# ESP32-C61 register map
Vendor: ESPRESSIF SYSTEMS (SHANGHAI) CO., LTD.; Series: ESP32 C-Series; File version: 1
CPU: RV32IMAC r0p0, little endian, no MPU, no FPU, 0 interrupt priority bits
Address unit: 32 bits
Registers are 32-bit, read-write, reset 0x0 unless marked. A register's access mark holds for its fields unless they carry their own. Offsets are from the block's base; [hi:lo] are bit positions; {n}, {i} and the like mark numbered series.

## CACHE (part 1 of 2) — CACHE Peripheral
Base 0x600C8000
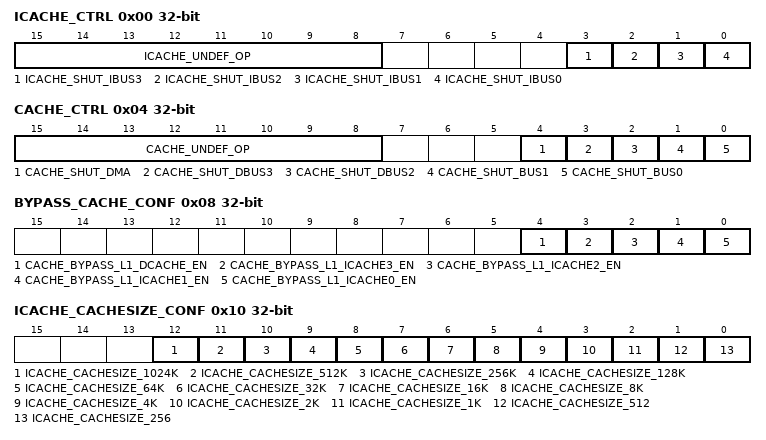
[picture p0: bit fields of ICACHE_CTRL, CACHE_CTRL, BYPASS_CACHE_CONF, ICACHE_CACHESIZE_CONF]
0x00 ICACHE_CTRL access per field — L1 instruction Cache(L1-ICache) control register
  [15:8] ICACHE_UNDEF_OP rw — Reserved
  [3] ICACHE_SHUT_IBUS3 ro — Reserved
  [2] ICACHE_SHUT_IBUS2 ro — Reserved
  [1] ICACHE_SHUT_IBUS1 rw — The bit is used to disable core1 ibus access L1-ICache, 0: enable, 1: disable
  [0] ICACHE_SHUT_IBUS0 rw — The bit is used to disable core0 ibus access L1-ICache, 0: enable, 1: disable
0x04 CACHE_CTRL access per field — L1 data Cache(L1-Cache) control register
  [15:8] CACHE_UNDEF_OP rw — Reserved
  [4] CACHE_SHUT_DMA ro — The bit is used to disable DMA access L1-Cache, 0: enable, 1: disable
  [3] CACHE_SHUT_DBUS3 ro — Reserved
  [2] CACHE_SHUT_DBUS2 ro — Reserved
  [1] CACHE_SHUT_BUS1 rw — The bit is used to disable core0 bus1 access L1-Cache, 0: enable, 1: disable
  [0] CACHE_SHUT_BUS0 rw — The bit is used to disable core0 bus0 access L1-Cache, 0: enable, 1: disable
0x08 BYPASS_CACHE_CONF ro — Bypass Cache configure register
  [4] CACHE_BYPASS_L1_DCACHE_EN — The bit is used to enable bypass L1-DCache. 0: disable bypass, 1: enable bypass.
  [3] CACHE_BYPASS_L1_ICACHE3_EN — Reserved
  [2] CACHE_BYPASS_L1_ICACHE2_EN — Reserved
  [1] CACHE_BYPASS_L1_ICACHE1_EN — The bit is used to enable bypass L1-ICache1. 0: disable bypass, 1: enable bypass.
  [0] CACHE_BYPASS_L1_ICACHE0_EN — The bit is used to enable bypass L1-ICache0. 0: disable bypass, 1: enable bypass.
0x0C CACHE_ATOMIC_CONF ro — L1 Cache atomic feature configure register
  [0] CACHE_ATOMIC_EN — The bit is used to enable atomic feature on L1-Cache when multiple cores access L1-Cache. 1: disable, 1: enable.
0x10 ICACHE_CACHESIZE_CONF ro — L1 instruction Cache CacheSize mode configure register
  [12] ICACHE_CACHESIZE_1024K — The field is used to configure cachesize of L1-ICache as 1024k bytes. This field and all other fields within this register is onehot.
  [11] ICACHE_CACHESIZE_512K — The field is used to configure cachesize of L1-ICache as 512k bytes. This field and all other fields within this register is onehot.
  [10] ICACHE_CACHESIZE_256K — The field is used to configure cachesize of L1-ICache as 256k bytes. This field and all other fields within this register is onehot.
  [9] ICACHE_CACHESIZE_128K — The field is used to configure cachesize of L1-ICache as 128k bytes. This field and all other fields within this register is onehot.
  [8] ICACHE_CACHESIZE_64K — The field is used to configure cachesize of L1-ICache as 64k bytes. This field and all other fields within this register is onehot.
  [7] ICACHE_CACHESIZE_32K — The field is used to configure cachesize of L1-ICache as 32k bytes. This field and all other fields within this register is onehot.
  [6] ICACHE_CACHESIZE_16K — The field is used to configure cachesize of L1-ICache as 16k bytes. This field and all other fields within this register is onehot.
  [5] ICACHE_CACHESIZE_8K — The field is used to configure cachesize of L1-ICache as 8k bytes. This field and all other fields within this register is onehot.
  [4] ICACHE_CACHESIZE_4K — The field is used to configure cachesize of L1-ICache as 4k bytes. This field and all other fields within this register is onehot.
  [3] ICACHE_CACHESIZE_2K — The field is used to configure cachesize of L1-ICache as 2k bytes. This field and all other fields within this register is onehot.
  [2] ICACHE_CACHESIZE_1K — The field is used to configure cachesize of L1-ICache as 1k bytes. This field and all other fields within this register is onehot.
  [1] ICACHE_CACHESIZE_512 — The field is used to configure cachesize of L1-ICache as 512 bytes. This field and all other fields within this register is onehot.
  [0] ICACHE_CACHESIZE_256 — The field is used to configure cachesize of L1-ICache as 256 bytes. This field and all other fields within this register is onehot.
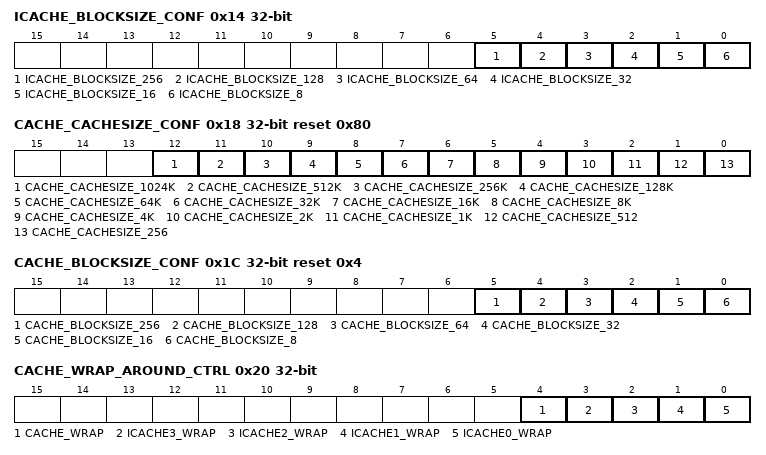
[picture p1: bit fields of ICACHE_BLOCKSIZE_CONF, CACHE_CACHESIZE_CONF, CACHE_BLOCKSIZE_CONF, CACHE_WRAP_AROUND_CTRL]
0x14 ICACHE_BLOCKSIZE_CONF ro — L1 instruction Cache BlockSize mode configure register
  [5] ICACHE_BLOCKSIZE_256 — The field is used to configureblocksize of L1-ICache as 256 bytes. This field and all other fields within this register is onehot.
  [4] ICACHE_BLOCKSIZE_128 — The field is used to configureblocksize of L1-ICache as 128 bytes. This field and all other fields within this register is onehot.
  [3] ICACHE_BLOCKSIZE_64 — The field is used to configureblocksize of L1-ICache as 64 bytes. This field and all other fields within this register is onehot.
  [2] ICACHE_BLOCKSIZE_32 — The field is used to configureblocksize of L1-ICache as 32 bytes. This field and all other fields within this register is onehot.
  [1] ICACHE_BLOCKSIZE_16 — The field is used to configureblocksize of L1-ICache as 16 bytes. This field and all other fields within this register is onehot.
  [0] ICACHE_BLOCKSIZE_8 — The field is used to configureblocksize of L1-ICache as 8 bytes. This field and all other fields within this register is onehot.
0x18 CACHE_CACHESIZE_CONF ro reset 0x80 — L1 data Cache CacheSize mode configure register
  [12] CACHE_CACHESIZE_1024K — The field is used to configure cachesize of L1-DCache as 1024k bytes. This field and all other fields within this register is onehot.
  [11] CACHE_CACHESIZE_512K — The field is used to configure cachesize of L1-DCache as 512k bytes. This field and all other fields within this register is onehot.
  [10] CACHE_CACHESIZE_256K — The field is used to configure cachesize of L1-DCache as 256k bytes. This field and all other fields within this register is onehot.
  [9] CACHE_CACHESIZE_128K — The field is used to configure cachesize of L1-DCache as 128k bytes. This field and all other fields within this register is onehot.
  [8] CACHE_CACHESIZE_64K — The field is used to configure cachesize of L1-DCache as 64k bytes. This field and all other fields within this register is onehot.
  [7] CACHE_CACHESIZE_32K — The field is used to configure cachesize of L1-DCache as 32k bytes. This field and all other fields within this register is onehot.
  [6] CACHE_CACHESIZE_16K — The field is used to configure cachesize of L1-DCache as 16k bytes. This field and all other fields within this register is onehot.
  [5] CACHE_CACHESIZE_8K — The field is used to configure cachesize of L1-DCache as 8k bytes. This field and all other fields within this register is onehot.
  [4] CACHE_CACHESIZE_4K — The field is used to configure cachesize of L1-DCache as 4k bytes. This field and all other fields within this register is onehot.
  [3] CACHE_CACHESIZE_2K — The field is used to configure cachesize of L1-DCache as 2k bytes. This field and all other fields within this register is onehot.
  [2] CACHE_CACHESIZE_1K — The field is used to configure cachesize of L1-DCache as 1k bytes. This field and all other fields within this register is onehot.
  [1] CACHE_CACHESIZE_512 — The field is used to configure cachesize of L1-DCache as 512 bytes. This field and all other fields within this register is onehot.
  [0] CACHE_CACHESIZE_256 — The field is used to configure cachesize of L1-DCache as 256 bytes. This field and all other fields within this register is onehot.
0x1C CACHE_BLOCKSIZE_CONF ro reset 0x4 — L1 data Cache BlockSize mode configure register
  [5] CACHE_BLOCKSIZE_256 — The field is used to configureblocksize of L1-DCache as 256 bytes. This field and all other fields within this register is onehot.
  [4] CACHE_BLOCKSIZE_128 — The field is used to configureblocksize of L1-DCache as 128 bytes. This field and all other fields within this register is onehot.
  [3] CACHE_BLOCKSIZE_64 — The field is used to configureblocksize of L1-DCache as 64 bytes. This field and all other fields within this register is onehot.
  [2] CACHE_BLOCKSIZE_32 — The field is used to configureblocksize of L1-DCache as 32 bytes. This field and all other fields within this register is onehot.
  [1] CACHE_BLOCKSIZE_16 — The field is used to configureblocksize of L1-DCache as 16 bytes. This field and all other fields within this register is onehot.
  [0] CACHE_BLOCKSIZE_8 — The field is used to configureblocksize of L1-DCache as 8 bytes. This field and all other fields within this register is onehot.
0x20 CACHE_WRAP_AROUND_CTRL access per field — Cache wrap around control register
  [4] CACHE_WRAP rw — Set this bit as 1 to enable L1-DCache wrap around mode.
  [3] ICACHE3_WRAP ro — Reserved
  [2] ICACHE2_WRAP ro — Reserved
  [1] ICACHE1_WRAP ro — Set this bit as 1 to enable L1-ICache1 wrap around mode.
  [0] ICACHE0_WRAP ro — Set this bit as 1 to enable L1-ICache0 wrap around mode.
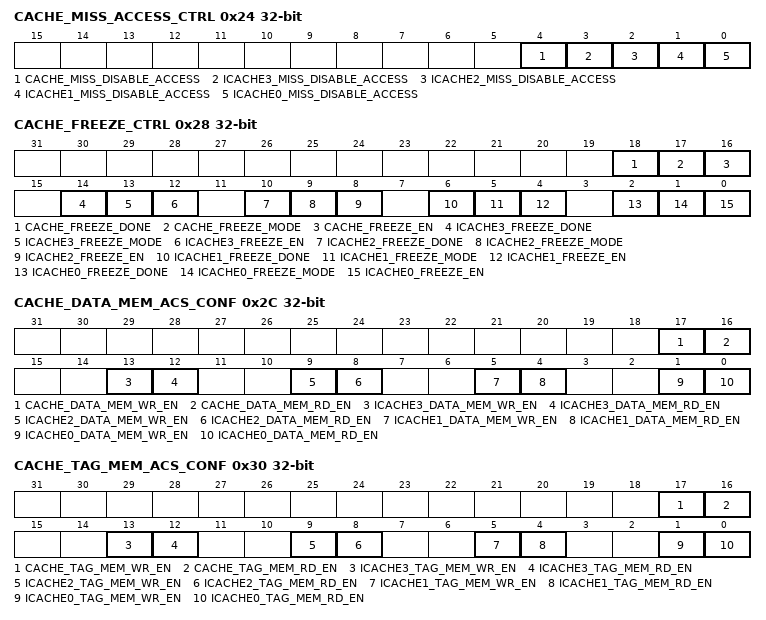
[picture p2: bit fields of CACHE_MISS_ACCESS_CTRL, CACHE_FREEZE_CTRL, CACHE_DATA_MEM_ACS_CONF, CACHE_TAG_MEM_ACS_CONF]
0x24 CACHE_MISS_ACCESS_CTRL access per field — Cache wrap around control register
  [4] CACHE_MISS_DISABLE_ACCESS rw — Set this bit as 1 to disable early restart of L1-DCache
  [3] ICACHE3_MISS_DISABLE_ACCESS ro — Reserved
  [2] ICACHE2_MISS_DISABLE_ACCESS ro — Reserved
  [1] ICACHE1_MISS_DISABLE_ACCESS ro — Set this bit as 1 to disable early restart of L1-ICache1
  [0] ICACHE0_MISS_DISABLE_ACCESS ro — Set this bit as 1 to disable early restart of L1-ICache0
0x28 CACHE_FREEZE_CTRL access per field — Cache Freeze control register
  [18] CACHE_FREEZE_DONE ro — The bit is used to indicate whether freeze operation on L1-Cache is finished or not. 0: not finished. 1: finished.
  [17] CACHE_FREEZE_MODE rw — The bit is used to configure mode of freeze operation L1-Cache. 0: a miss-access will not stuck. 1: a miss-access will stuck.
  [16] CACHE_FREEZE_EN rw — The bit is used to enable freeze operation on L1-Cache. It can be cleared by software.
  [14] ICACHE3_FREEZE_DONE ro — Reserved
  [13] ICACHE3_FREEZE_MODE ro — Reserved
  [12] ICACHE3_FREEZE_EN ro — Reserved
  [10] ICACHE2_FREEZE_DONE ro — Reserved
  [9] ICACHE2_FREEZE_MODE ro — Reserved
  [8] ICACHE2_FREEZE_EN ro — Reserved
  [6] ICACHE1_FREEZE_DONE ro — The bit is used to indicate whether freeze operation on L1-ICache1 is finished or not. 0: not finished. 1: finished.
  [5] ICACHE1_FREEZE_MODE ro — The bit is used to configure mode of freeze operation L1-ICache1. 0: a miss-access will not stuck. 1: a miss-access will stuck.
  [4] ICACHE1_FREEZE_EN ro — The bit is used to enable freeze operation on L1-ICache1. It can be cleared by software.
  [2] ICACHE0_FREEZE_DONE ro — The bit is used to indicate whether freeze operation on L1-ICache0 is finished or not. 0: not finished. 1: finished.
  [1] ICACHE0_FREEZE_MODE ro — The bit is used to configure mode of freeze operation L1-ICache0. 0: a miss-access will not stuck. 1: a miss-access will stuck.
  [0] ICACHE0_FREEZE_EN ro — The bit is used to enable freeze operation on L1-ICache0. It can be cleared by software.
0x2C CACHE_DATA_MEM_ACS_CONF access per field — Cache data memory access configure register
  [17] CACHE_DATA_MEM_WR_EN rw — The bit is used to enable config-bus write L1-Cache data memoryory. 0: disable, 1: enable.
  [16] CACHE_DATA_MEM_RD_EN rw — The bit is used to enable config-bus read L1-Cache data memoryory. 0: disable, 1: enable.
  [13] ICACHE3_DATA_MEM_WR_EN ro — Reserved
  [12] ICACHE3_DATA_MEM_RD_EN ro — Reserved
  [9] ICACHE2_DATA_MEM_WR_EN ro — Reserved
  [8] ICACHE2_DATA_MEM_RD_EN ro — Reserved
  [5] ICACHE1_DATA_MEM_WR_EN ro — The bit is used to enable config-bus write L1-ICache1 data memoryory. 0: disable, 1: enable.
  [4] ICACHE1_DATA_MEM_RD_EN ro — The bit is used to enable config-bus read L1-ICache1 data memoryory. 0: disable, 1: enable.
  [1] ICACHE0_DATA_MEM_WR_EN ro — The bit is used to enable config-bus write L1-ICache0 data memoryory. 0: disable, 1: enable.
  [0] ICACHE0_DATA_MEM_RD_EN ro — The bit is used to enable config-bus read L1-ICache0 data memoryory. 0: disable, 1: enable.
0x30 CACHE_TAG_MEM_ACS_CONF access per field — Cache tag memory access configure register
  [17] CACHE_TAG_MEM_WR_EN rw — The bit is used to enable config-bus write L1-Cache tag memoryory. 0: disable, 1: enable.
  [16] CACHE_TAG_MEM_RD_EN rw — The bit is used to enable config-bus read L1-Cache tag memoryory. 0: disable, 1: enable.
  [13] ICACHE3_TAG_MEM_WR_EN ro — Reserved
  [12] ICACHE3_TAG_MEM_RD_EN ro — Reserved
  [9] ICACHE2_TAG_MEM_WR_EN ro — Reserved
  [8] ICACHE2_TAG_MEM_RD_EN ro — Reserved
  [5] ICACHE1_TAG_MEM_WR_EN ro — The bit is used to enable config-bus write L1-ICache1 tag memoryory. 0: disable, 1: enable.
  [4] ICACHE1_TAG_MEM_RD_EN ro — The bit is used to enable config-bus read L1-ICache1 tag memoryory. 0: disable, 1: enable.
  [1] ICACHE0_TAG_MEM_WR_EN ro — The bit is used to enable config-bus write L1-ICache0 tag memoryory. 0: disable, 1: enable.
  [0] ICACHE0_TAG_MEM_RD_EN ro — The bit is used to enable config-bus read L1-ICache0 tag memoryory. 0: disable, 1: enable.
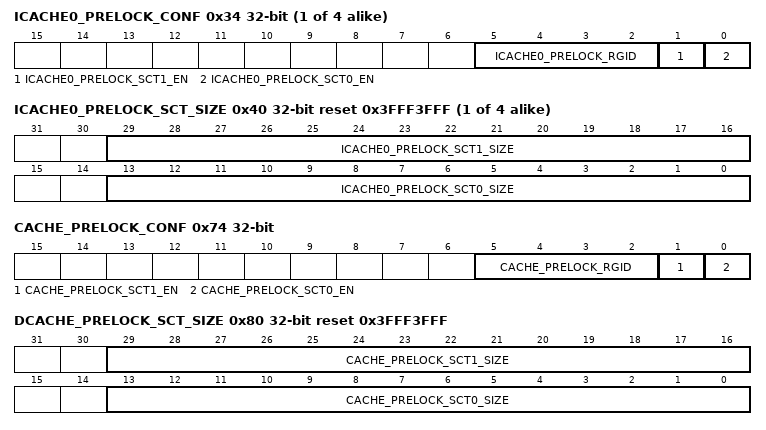
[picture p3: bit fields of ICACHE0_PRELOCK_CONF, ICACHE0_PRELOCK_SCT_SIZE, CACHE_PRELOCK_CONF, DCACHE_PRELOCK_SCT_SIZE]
{0x34+0x10*i} ICACHE{i}_PRELOCK_CONF ro (i=0..3) — L1 instruction Cache {i} prelock configure register
  [5:2] ICACHE{i}_PRELOCK_RGID — The bit is used to set the gid of l1 icache{i} prelock.
  [1] ICACHE{i}_PRELOCK_SCT1_EN — The bit is used to enable the second section of prelock function on L1-ICache{i}.
  [0] ICACHE{i}_PRELOCK_SCT0_EN — The bit is used to enable the first section of prelock function on L1-ICache{i}.
{0x38+0x10*i} ICACHE{i}_PRELOCK_SCT0_ADDR ro (i=0..3) — L1 instruction Cache {i} prelock section0 address configure register
  [31:0] ICACHE{i}_PRELOCK_SCT0_ADDR — Those bits are used to configure the start address of the first section of prelock on L1-ICache{i}, which should be used together with L1_ICACHE{i}_PRELOCK_SCT0_SIZE_REG
{0x3C+0x10*i} ICACHE{i}_PRELOCK_SCT1_ADDR ro (i=0..3) — L1 instruction Cache {i} prelock section1 address configure register
  [31:0] ICACHE{i}_PRELOCK_SCT1_ADDR — Those bits are used to configure the start address of the second section of prelock on L1-ICache{i}, which should be used together with L1_ICACHE{i}_PRELOCK_SCT1_SIZE_REG
{0x40+0x10*i} ICACHE{i}_PRELOCK_SCT_SIZE ro reset 0x3FFF3FFF (i=0..3) — L1 instruction Cache {i} prelock section size configure register
  [29:16] ICACHE{i}_PRELOCK_SCT1_SIZE — Those bits are used to configure the size of the second section of prelock on L1-ICache{i}, which should be used together with L1_ICACHE{i}_PRELOCK_SCT1_ADDR_REG
  [13:0] ICACHE{i}_PRELOCK_SCT0_SIZE — Those bits are used to configure the size of the first section of prelock on L1-ICache{i}, which should be used together with L1_ICACHE{i}_PRELOCK_SCT0_ADDR_REG
0x74 CACHE_PRELOCK_CONF access per field — L1 Cache prelock configure register
  [5:2] CACHE_PRELOCK_RGID ro — The bit is used to set the gid of l1 cache prelock.
  [1] CACHE_PRELOCK_SCT1_EN rw — The bit is used to enable the second section of prelock function on L1-Cache.
  [0] CACHE_PRELOCK_SCT0_EN rw — The bit is used to enable the first section of prelock function on L1-Cache.
0x78 CACHE_PRELOCK_SCT0_ADDR — L1 Cache prelock section0 address configure register
  [31:0] CACHE_PRELOCK_SCT0_ADDR — Those bits are used to configure the start address of the first section of prelock on L1-Cache, which should be used together with L1_CACHE_PRELOCK_SCT0_SIZE_REG
0x7C DCACHE_PRELOCK_SCT1_ADDR — L1 Cache prelock section1 address configure register
  [31:0] CACHE_PRELOCK_SCT1_ADDR — Those bits are used to configure the start address of the second section of prelock on L1-Cache, which should be used together with L1_CACHE_PRELOCK_SCT1_SIZE_REG
0x80 DCACHE_PRELOCK_SCT_SIZE reset 0x3FFF3FFF — L1 Cache prelock section size configure register
  [29:16] CACHE_PRELOCK_SCT1_SIZE — Those bits are used to configure the size of the second section of prelock on L1-Cache, which should be used together with L1_CACHE_PRELOCK_SCT1_ADDR_REG
  [13:0] CACHE_PRELOCK_SCT0_SIZE — Those bits are used to configure the size of the first section of prelock on L1-Cache, which should be used together with L1_CACHE_PRELOCK_SCT0_ADDR_REG
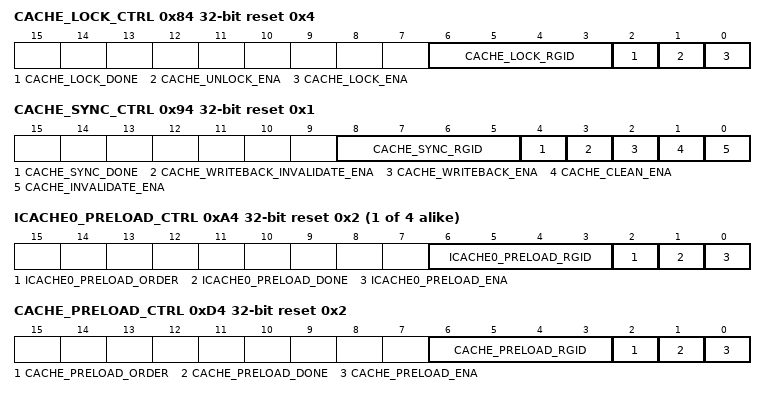
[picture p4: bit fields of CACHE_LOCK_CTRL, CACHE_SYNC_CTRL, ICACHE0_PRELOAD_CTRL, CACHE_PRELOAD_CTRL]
0x84 CACHE_LOCK_CTRL access per field reset 0x4 — Lock-class (manual lock) operation control register
  [6:3] CACHE_LOCK_RGID ro — The bit is used to set the gid of cache lock/unlock.
  [2] CACHE_LOCK_DONE ro — The bit is used to indicate whether unlock/lock operation is finished or not. 0: not finished. 1: finished.
  [1] CACHE_UNLOCK_ENA rw — The bit is used to enable unlock operation. It will be cleared by hardware after unlock operation done
  [0] CACHE_LOCK_ENA rw — The bit is used to enable lock operation. It will be cleared by hardware after lock operation done
0x88 CACHE_LOCK_MAP — Lock (manual lock) map configure register
  [5:0] CACHE_LOCK_MAP — Those bits are used to indicate which caches in the two-level cache structure will apply this lock/unlock operation. [4]: L1-Cache
0x8C CACHE_LOCK_ADDR — Lock (manual lock) address configure register
  [31:0] CACHE_LOCK_ADDR — Those bits are used to configure the start address of the lock/unlock operation, which should be used together with CACHE_LOCK_SIZE_REG
0x90 CACHE_LOCK_SIZE — Lock (manual lock) size configure register
  [15:0] CACHE_LOCK_SIZE — Those bits are used to configure the size of the lock/unlock operation, which should be used together with CACHE_LOCK_ADDR_REG
0x94 CACHE_SYNC_CTRL access per field reset 0x1 — Sync-class operation control register
  [8:5] CACHE_SYNC_RGID ro — The bit is used to set the gid of cache sync operation (invalidate, clean, writeback, writeback_invalidate)
  [4] CACHE_SYNC_DONE ro — The bit is used to indicate whether sync operation (invalidate, clean, writeback, writeback_invalidate) is finished or not. 0: not finished. 1: finished.
  [3] CACHE_WRITEBACK_INVALIDATE_ENA rw — The bit is used to enable writeback-invalidate operation. It will be cleared by hardware after writeback-invalidate operation done. Note that this bit and the other sync-bits (invalidate_ena, clean_ena, writeback_ena) are mutually exclusive, that is, those bits can not be set to 1 at the same time.
  [2] CACHE_WRITEBACK_ENA rw — The bit is used to enable writeback operation. It will be cleared by hardware after writeback operation done. Note that this bit and the other sync-bits (invalidate_ena, clean_ena, writeback_invalidate_ena) are mutually exclusive, that is, those bits can not be set to 1 at the same time.
  [1] CACHE_CLEAN_ENA rw — The bit is used to enable clean operation. It will be cleared by hardware after clean operation done. Note that this bit and the other sync-bits (invalidate_ena, writeback_ena, writeback_invalidate_ena) are mutually exclusive, that is, those bits can not be set to 1 at the same time.
  [0] CACHE_INVALIDATE_ENA rw — The bit is used to enable invalidate operation. It will be cleared by hardware after invalidate operation done. Note that this bit and the other sync-bits (clean_ena, writeback_ena, writeback_invalidate_ena) are mutually exclusive, that is, those bits can not be set to 1 at the same time.
0x98 CACHE_SYNC_MAP reset 0x3F — Sync map configure register
  [5:0] CACHE_SYNC_MAP — Those bits are used to indicate which caches in the two-level cache structure will apply the sync operation. [4]: L1-Cache
0x9C CACHE_SYNC_ADDR — Sync address configure register
  [31:0] CACHE_SYNC_ADDR — Those bits are used to configure the start address of the sync operation, which should be used together with CACHE_SYNC_SIZE_REG
0xA0 CACHE_SYNC_SIZE — Sync size configure register
  [24:0] CACHE_SYNC_SIZE — Those bits are used to configure the size of the sync operation, which should be used together with CACHE_SYNC_ADDR_REG
{0xA4+0xC*i} ICACHE{i}_PRELOAD_CTRL access per field reset 0x2 (i=0..3) — L1 instruction Cache {i} preload-operation control register
  [6:3] ICACHE{i}_PRELOAD_RGID ro — The bit is used to set the gid of l1 icache{i} preload.
  [2] ICACHE{i}_PRELOAD_ORDER ro — The bit is used to configure the direction of preload operation. 0: ascending, 1: descending.
  [1] ICACHE{i}_PRELOAD_DONE ro — The bit is used to indicate whether preload operation is finished or not. 0: not finished. 1: finished.
  [0] ICACHE{i}_PRELOAD_ENA rw — The bit is used to enable preload operation on L1-ICache{i}. It will be cleared by hardware automatically after preload operation is done.
{0xA8+0xC*i} ICACHE{i}_PRELOAD_ADDR ro (i=0..3) — L1 instruction Cache {i} preload address configure register
  [31:0] ICACHE{i}_PRELOAD_ADDR — Those bits are used to configure the start address of preload on L1-ICache{i}, which should be used together with L1_ICACHE{i}_PRELOAD_SIZE_REG
{0xAC+0xC*i} ICACHE{i}_PRELOAD_SIZE ro (i=0..3) — L1 instruction Cache {i} preload size configure register
  [13:0] ICACHE{i}_PRELOAD_SIZE — Those bits are used to configure the size of the first section of prelock on L1-ICache{i}, which should be used together with L1_ICACHE{i}_PRELOAD_ADDR_REG
0xD4 CACHE_PRELOAD_CTRL access per field reset 0x2 — L1 Cache preload-operation control register
  [6:3] CACHE_PRELOAD_RGID ro — The bit is used to set the gid of l1 cache preload.
  [2] CACHE_PRELOAD_ORDER rw — The bit is used to configure the direction of preload operation. 0: ascending, 1: descending.
  [1] CACHE_PRELOAD_DONE ro — The bit is used to indicate whether preload operation is finished or not. 0: not finished. 1: finished.
  [0] CACHE_PRELOAD_ENA rw — The bit is used to enable preload operation on L1-Cache. It will be cleared by hardware automatically after preload operation is done.
0xD8 DCACHE_PRELOAD_ADDR — L1 Cache preload address configure register
  [31:0] CACHE_PRELOAD_ADDR — Those bits are used to configure the start address of preload on L1-Cache, which should be used together with L1_CACHE_PRELOAD_SIZE_REG
0xDC DCACHE_PRELOAD_SIZE — L1 Cache preload size configure register
  [13:0] CACHE_PRELOAD_SIZE — Those bits are used to configure the size of the first section of prelock on L1-Cache, which should be used together with L1_CACHE_PRELOAD_ADDR_REG
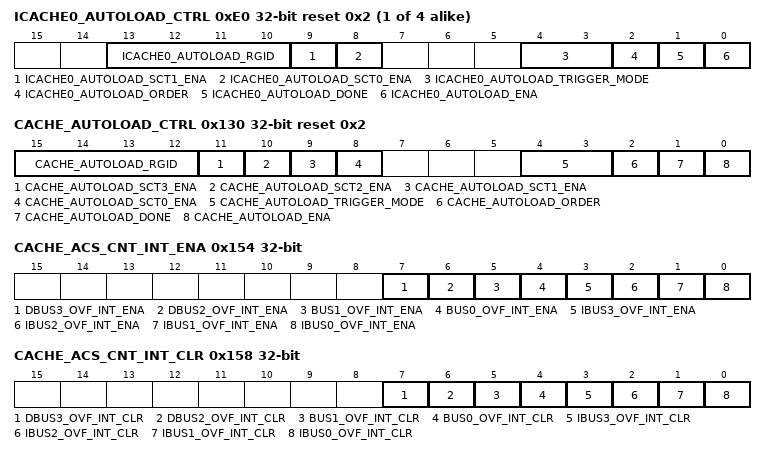
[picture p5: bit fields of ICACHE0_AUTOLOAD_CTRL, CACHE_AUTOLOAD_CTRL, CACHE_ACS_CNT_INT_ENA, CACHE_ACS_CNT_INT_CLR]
{0xE0+0x14*i} ICACHE{i}_AUTOLOAD_CTRL ro reset 0x2 (i=0..3) — L1 instruction Cache {i} autoload-operation control register
  [13:10] ICACHE{i}_AUTOLOAD_RGID — The bit is used to set the gid of l1 icache{i} autoload.
  [9] ICACHE{i}_AUTOLOAD_SCT1_ENA — The bit is used to enable the second section for autoload operation on L1-ICache{i}.
  [8] ICACHE{i}_AUTOLOAD_SCT0_ENA — The bit is used to enable the first section for autoload operation on L1-ICache{i}.
  [4:3] ICACHE{i}_AUTOLOAD_TRIGGER_MODE — The field is used to configure trigger mode of autoload operation on L1-ICache{i}. 0/3: miss-trigger, 1: hit-trigger, 2: miss-hit-trigger.
  [2] ICACHE{i}_AUTOLOAD_ORDER — The bit is used to configure the direction of autoload operation on L1-ICache{i}. 0: ascending. 1: descending.
  [1] ICACHE{i}_AUTOLOAD_DONE — The bit is used to indicate whether autoload operation on L1-ICache{i} is finished or not. 0: not finished. 1: finished.
  [0] ICACHE{i}_AUTOLOAD_ENA — The bit is used to enable and disable autoload operation on L1-ICache{i}. 1: enable, 0: disable.
{0xE4+0x14*i} ICACHE{i}_AUTOLOAD_SCT0_ADDR ro (i=0..3) — L1 instruction Cache {i} autoload section 0 address configure register
  [31:0] ICACHE{i}_AUTOLOAD_SCT0_ADDR — Those bits are used to configure the start address of the first section for autoload operation on L1-ICache{i}. Note that it should be used together with L1_ICACHE{i}_AUTOLOAD_SCT0_SIZE and L1_ICACHE_AUTOLOAD_SCT0_ENA.
{0xE8+0x14*i} ICACHE{i}_AUTOLOAD_SCT0_SIZE ro (i=0..3) — L1 instruction Cache {i} autoload section 0 size configure register
  [27:0] ICACHE{i}_AUTOLOAD_SCT0_SIZE — Those bits are used to configure the size of the first section for autoload operation on L1-ICache{i}. Note that it should be used together with L1_ICACHE{i}_AUTOLOAD_SCT0_ADDR and L1_ICACHE_AUTOLOAD_SCT0_ENA.
{0xEC+0x14*i} ICACHE{i}_AUTOLOAD_SCT1_ADDR ro (i=0..3) — L1 instruction Cache {i} autoload section 1 address configure register
  [31:0] ICACHE{i}_AUTOLOAD_SCT1_ADDR — Those bits are used to configure the start address of the second section for autoload operation on L1-ICache{i}. Note that it should be used together with L1_ICACHE{i}_AUTOLOAD_SCT1_SIZE and L1_ICACHE_AUTOLOAD_SCT1_ENA.
{0xF0+0x14*i} ICACHE{i}_AUTOLOAD_SCT1_SIZE ro (i=0..2) — L1 instruction Cache {i} autoload section 1 size configure register
  [27:0] ICACHE{i}_AUTOLOAD_SCT1_SIZE — Those bits are used to configure the size of the second section for autoload operation on L1-ICache{i}. Note that it should be used together with L1_ICACHE{i}_AUTOLOAD_SCT1_ADDR and L1_ICACHE_AUTOLOAD_SCT1_ENA.
0x12C ICACHE3_AUTOLOAD_SCT1_SIZE ro — L1 instruction Cache 3 autoload section 1 size configure register
  [27:0] ICACHE3_AUTOLOAD_SCT1_SIZE — Reserved
0x130 CACHE_AUTOLOAD_CTRL access per field reset 0x2 — L1 Cache autoload-operation control register
  [15:12] CACHE_AUTOLOAD_RGID ro — The bit is used to set the gid of l1 cache autoload.
  [11] CACHE_AUTOLOAD_SCT3_ENA ro — The bit is used to enable the fourth section for autoload operation on L1-Cache.
  [10] CACHE_AUTOLOAD_SCT2_ENA ro — The bit is used to enable the third section for autoload operation on L1-Cache.
  [9] CACHE_AUTOLOAD_SCT1_ENA rw — The bit is used to enable the second section for autoload operation on L1-Cache.
  [8] CACHE_AUTOLOAD_SCT0_ENA rw — The bit is used to enable the first section for autoload operation on L1-Cache.
  [4:3] CACHE_AUTOLOAD_TRIGGER_MODE rw — The field is used to configure trigger mode of autoload operation on L1-Cache. 0/3: miss-trigger, 1: hit-trigger, 2: miss-hit-trigger.
  [2] CACHE_AUTOLOAD_ORDER rw — The bit is used to configure the direction of autoload operation on L1-Cache. 0: ascending. 1: descending.
  [1] CACHE_AUTOLOAD_DONE ro — The bit is used to indicate whether autoload operation on L1-Cache is finished or not. 0: not finished. 1: finished.
  [0] CACHE_AUTOLOAD_ENA rw — The bit is used to enable and disable autoload operation on L1-Cache. 1: enable, 0: disable.
0x134 CACHE_AUTOLOAD_SCT0_ADDR — L1 Cache autoload section 0 address configure register
  [31:0] CACHE_AUTOLOAD_SCT0_ADDR — Those bits are used to configure the start address of the first section for autoload operation on L1-Cache. Note that it should be used together with L1_CACHE_AUTOLOAD_SCT0_SIZE and L1_CACHE_AUTOLOAD_SCT0_ENA.
0x138 CACHE_AUTOLOAD_SCT0_SIZE — L1 Cache autoload section 0 size configure register
  [24:0] CACHE_AUTOLOAD_SCT0_SIZE — Those bits are used to configure the size of the first section for autoload operation on L1-Cache. Note that it should be used together with L1_CACHE_AUTOLOAD_SCT0_ADDR and L1_CACHE_AUTOLOAD_SCT0_ENA.
0x13C CACHE_AUTOLOAD_SCT1_ADDR — L1 Cache autoload section 1 address configure register
  [31:0] CACHE_AUTOLOAD_SCT1_ADDR — Those bits are used to configure the start address of the second section for autoload operation on L1-Cache. Note that it should be used together with L1_CACHE_AUTOLOAD_SCT1_SIZE and L1_CACHE_AUTOLOAD_SCT1_ENA.
0x140 CACHE_AUTOLOAD_SCT1_SIZE — L1 Cache autoload section 1 size configure register
  [24:0] CACHE_AUTOLOAD_SCT1_SIZE — Those bits are used to configure the size of the second section for autoload operation on L1-Cache. Note that it should be used together with L1_CACHE_AUTOLOAD_SCT1_ADDR and L1_CACHE_AUTOLOAD_SCT1_ENA.
0x144 CACHE_AUTOLOAD_SCT2_ADDR ro — L1 Cache autoload section 2 address configure register
  [31:0] CACHE_AUTOLOAD_SCT2_ADDR — Those bits are used to configure the start address of the third section for autoload operation on L1-Cache. Note that it should be used together with L1_CACHE_AUTOLOAD_SCT2_SIZE and L1_CACHE_AUTOLOAD_SCT2_ENA.
0x148 CACHE_AUTOLOAD_SCT2_SIZE ro — L1 Cache autoload section 2 size configure register
  [24:0] CACHE_AUTOLOAD_SCT2_SIZE — Those bits are used to configure the size of the third section for autoload operation on L1-Cache. Note that it should be used together with L1_CACHE_AUTOLOAD_SCT2_ADDR and L1_CACHE_AUTOLOAD_SCT2_ENA.
0x14C CACHE_AUTOLOAD_SCT3_ADDR ro — L1 Cache autoload section 1 address configure register
  [31:0] CACHE_AUTOLOAD_SCT3_ADDR — Those bits are used to configure the start address of the fourth section for autoload operation on L1-Cache. Note that it should be used together with L1_CACHE_AUTOLOAD_SCT3_SIZE and L1_CACHE_AUTOLOAD_SCT3_ENA.
0x150 CACHE_AUTOLOAD_SCT3_SIZE ro — L1 Cache autoload section 1 size configure register
  [24:0] CACHE_AUTOLOAD_SCT3_SIZE — Those bits are used to configure the size of the fourth section for autoload operation on L1-Cache. Note that it should be used together with L1_CACHE_AUTOLOAD_SCT3_ADDR and L1_CACHE_AUTOLOAD_SCT3_ENA.
0x154 CACHE_ACS_CNT_INT_ENA access per field — Cache Access Counter Interrupt enable register
  [7] DBUS3_OVF_INT_ENA ro — Reserved
  [6] DBUS2_OVF_INT_ENA ro — Reserved
  [5] BUS1_OVF_INT_ENA rw — The bit is used to enable interrupt of one of counters overflow that occurs in L1-DCache due to bus1 accesses L1-DCache.
  [4] BUS0_OVF_INT_ENA rw — The bit is used to enable interrupt of one of counters overflow that occurs in L1-DCache due to bus0 accesses L1-DCache.
  [3] IBUS3_OVF_INT_ENA ro — Reserved
  [2] IBUS2_OVF_INT_ENA ro — Reserved
  [1] IBUS1_OVF_INT_ENA ro — The bit is used to enable interrupt of one of counters overflow that occurs in L1-ICache1 due to bus1 accesses L1-ICache1.
  [0] IBUS0_OVF_INT_ENA ro — The bit is used to enable interrupt of one of counters overflow that occurs in L1-ICache0 due to bus0 accesses L1-ICache0.
0x158 CACHE_ACS_CNT_INT_CLR access per field — Cache Access Counter Interrupt clear register
  [7] DBUS3_OVF_INT_CLR rw — Reserved
  [6] DBUS2_OVF_INT_CLR rw — Reserved
  [5] BUS1_OVF_INT_CLR wo — The bit is used to clear counters overflow interrupt and counters in L1-DCache due to bus1 accesses L1-DCache.
  [4] BUS0_OVF_INT_CLR wo — The bit is used to clear counters overflow interrupt and counters in L1-DCache due to bus0 accesses L1-DCache.
  [3] IBUS3_OVF_INT_CLR ro — Reserved
  [2] IBUS2_OVF_INT_CLR ro — Reserved
  [1] IBUS1_OVF_INT_CLR ro — The bit is used to clear counters overflow interrupt and counters in L1-ICache1 due to bus1 accesses L1-ICache1.
  [0] IBUS0_OVF_INT_CLR ro — The bit is used to clear counters overflow interrupt and counters in L1-ICache0 due to bus0 accesses L1-ICache0.
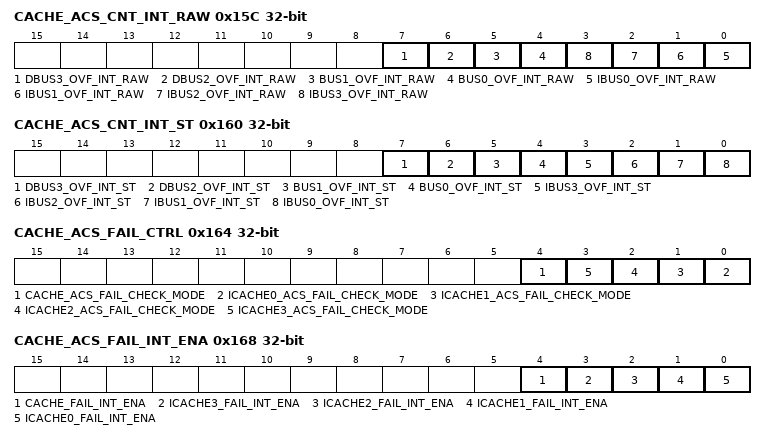
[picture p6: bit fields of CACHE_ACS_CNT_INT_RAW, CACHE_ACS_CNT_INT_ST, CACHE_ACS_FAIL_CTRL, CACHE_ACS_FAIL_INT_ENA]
0x15C CACHE_ACS_CNT_INT_RAW — Cache Access Counter Interrupt raw register
  [7] DBUS3_OVF_INT_RAW — The raw bit of the interrupt of one of counters overflow that occurs in L1-DCache due to bus3 accesses L1-DCache.
  [6] DBUS2_OVF_INT_RAW — The raw bit of the interrupt of one of counters overflow that occurs in L1-DCache due to bus2 accesses L1-DCache.
  [5] BUS1_OVF_INT_RAW — The raw bit of the interrupt of one of counters overflow that occurs in L1-DCache due to bus1 accesses L1-DCache.
  [4] BUS0_OVF_INT_RAW — The raw bit of the interrupt of one of counters overflow that occurs in L1-DCache due to bus0 accesses L1-DCache.
  [n] IBUS{n}_OVF_INT_RAW (n=0..3) — The raw bit of the interrupt of one of counters overflow that occurs in L1-ICache{n} due to bus{n} accesses L1-ICache{n}.
0x160 CACHE_ACS_CNT_INT_ST ro — Cache Access Counter Interrupt status register
  [7] DBUS3_OVF_INT_ST — Reserved
  [6] DBUS2_OVF_INT_ST — Reserved
  [5] BUS1_OVF_INT_ST — The bit indicates the interrupt status of one of counters overflow that occurs in L1-DCache due to bus1 accesses L1-DCache.
  [4] BUS0_OVF_INT_ST — The bit indicates the interrupt status of one of counters overflow that occurs in L1-DCache due to bus0 accesses L1-DCache.
  [3] IBUS3_OVF_INT_ST — Reserved
  [2] IBUS2_OVF_INT_ST — Reserved
  [1] IBUS1_OVF_INT_ST — The bit indicates the interrupt status of one of counters overflow that occurs in L1-ICache1 due to bus1 accesses L1-ICache1.
  [0] IBUS0_OVF_INT_ST — The bit indicates the interrupt status of one of counters overflow that occurs in L1-ICache0 due to bus0 accesses L1-ICache0.
0x164 CACHE_ACS_FAIL_CTRL access per field — Cache Access Fail Configuration register
  [4] CACHE_ACS_FAIL_CHECK_MODE rw — The bit is used to configure l1 cache access fail check mode. 0: the access fail is not propagated to the request, 1: the access fail is propagated to the request
  [n] ICACHE{n}_ACS_FAIL_CHECK_MODE ro (n=0..3) — The bit is used to configure l1 icache{n} access fail check mode. 0: the access fail is not propagated to the request, 1: the access fail is propagated to the request
0x168 CACHE_ACS_FAIL_INT_ENA access per field — Cache Access Fail Interrupt enable register
  [4] CACHE_FAIL_INT_ENA rw — The bit is used to enable interrupt of access fail that occurs in L1-DCache due to cpu accesses L1-DCache.
  [3] ICACHE3_FAIL_INT_ENA ro — Reserved
  [2] ICACHE2_FAIL_INT_ENA ro — Reserved
  [1] ICACHE1_FAIL_INT_ENA ro — The bit is used to enable interrupt of access fail that occurs in L1-ICache1 due to cpu accesses L1-ICache1.
  [0] ICACHE0_FAIL_INT_ENA ro — The bit is used to enable interrupt of access fail that occurs in L1-ICache0 due to cpu accesses L1-ICache0.
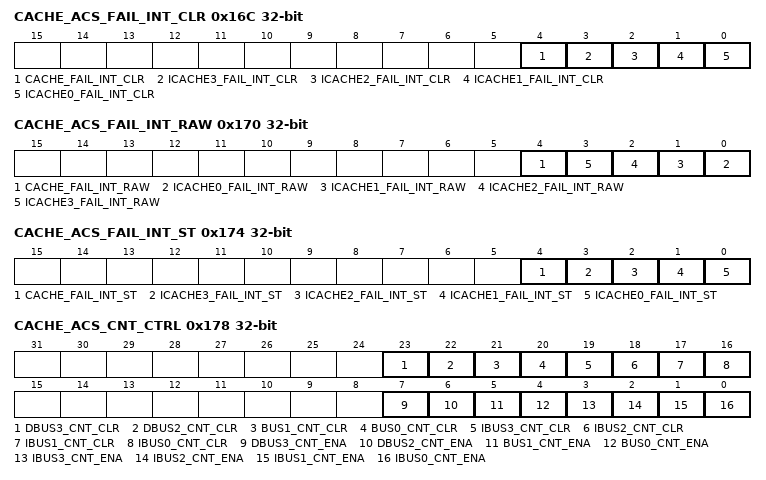
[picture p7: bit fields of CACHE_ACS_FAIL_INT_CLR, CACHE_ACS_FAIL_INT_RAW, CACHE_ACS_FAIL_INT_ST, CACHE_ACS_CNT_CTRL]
0x16C CACHE_ACS_FAIL_INT_CLR wo — L1-Cache Access Fail Interrupt clear register
  [4] CACHE_FAIL_INT_CLR — The bit is used to clear interrupt of access fail that occurs in L1-DCache due to cpu accesses L1-DCache.
  [3] ICACHE3_FAIL_INT_CLR — Reserved
  [2] ICACHE2_FAIL_INT_CLR — Reserved
  [1] ICACHE1_FAIL_INT_CLR — The bit is used to clear interrupt of access fail that occurs in L1-ICache1 due to cpu accesses L1-ICache1.
  [0] ICACHE0_FAIL_INT_CLR — The bit is used to clear interrupt of access fail that occurs in L1-ICache0 due to cpu accesses L1-ICache0.
0x170 CACHE_ACS_FAIL_INT_RAW — Cache Access Fail Interrupt raw register
  [4] CACHE_FAIL_INT_RAW — The raw bit of the interrupt of access fail that occurs in L1-DCache.
  [n] ICACHE{n}_FAIL_INT_RAW (n=0..3) — The raw bit of the interrupt of access fail that occurs in L1-ICache{n}.
0x174 CACHE_ACS_FAIL_INT_ST ro — Cache Access Fail Interrupt status register
  [4] CACHE_FAIL_INT_ST — The bit indicates the interrupt status of access fail that occurs in L1-DCache due to cpu accesses L1-DCache.
  [3] ICACHE3_FAIL_INT_ST — Reserved
  [2] ICACHE2_FAIL_INT_ST — Reserved
  [1] ICACHE1_FAIL_INT_ST — The bit indicates the interrupt status of access fail that occurs in L1-ICache1 due to cpu accesses L1-ICache.
  [0] ICACHE0_FAIL_INT_ST — The bit indicates the interrupt status of access fail that occurs in L1-ICache0 due to cpu accesses L1-ICache.
0x178 CACHE_ACS_CNT_CTRL access per field — Cache Access Counter enable and clear register
  [23] DBUS3_CNT_CLR ro — Reserved
  [22] DBUS2_CNT_CLR ro — Reserved
  [21] BUS1_CNT_CLR wo — The bit is used to clear dbus1 counter in L1-DCache.
  [20] BUS0_CNT_CLR wo — The bit is used to clear dbus0 counter in L1-DCache.
  [19] IBUS3_CNT_CLR wo — Reserved
  [18] IBUS2_CNT_CLR wo — Reserved
  [17] IBUS1_CNT_CLR wo — The bit is used to clear ibus1 counter in L1-ICache1.
  [16] IBUS0_CNT_CLR wo — The bit is used to clear ibus0 counter in L1-ICache0.
  [7] DBUS3_CNT_ENA ro — Reserved
  [6] DBUS2_CNT_ENA ro — Reserved
  [5] BUS1_CNT_ENA rw — The bit is used to enable dbus1 counter in L1-DCache.
  [4] BUS0_CNT_ENA rw — The bit is used to enable dbus0 counter in L1-DCache.
  [3] IBUS3_CNT_ENA ro — Reserved
  [2] IBUS2_CNT_ENA ro — Reserved
  [1] IBUS1_CNT_ENA ro — The bit is used to enable ibus1 counter in L1-ICache1.
  [0] IBUS0_CNT_ENA ro — The bit is used to enable ibus0 counter in L1-ICache0.
{0x17C+0x10*i} IBUS{i}_ACS_HIT_CNT ro (i=0..3) — L1-ICache bus{i} Hit-Access Counter register
  [31:0] IBUS{i}_HIT_CNT — The register records the number of hits when bus{i} accesses L1-ICache{i}.
{0x180+0x10*i} IBUS{i}_ACS_MISS_CNT ro (i=0..3) — L1-ICache bus{i} Miss-Access Counter register
  [31:0] IBUS{i}_MISS_CNT — The register records the number of missing when bus{i} accesses L1-ICache{i}.
{0x184+0x10*i} IBUS{i}_ACS_CONFLICT_CNT ro (i=0..3) — L1-ICache bus{i} Conflict-Access Counter register
  [31:0] IBUS{i}_CONFLICT_CNT — The register records the number of access-conflicts when bus{i} accesses L1-ICache{i}.
{0x188+0x10*i} IBUS{i}_ACS_NXTLVL_RD_CNT ro (i=0..3) — L1-ICache bus{i} Next-Level-Access Counter register
  [31:0] IBUS{i}_NXTLVL_RD_CNT — The register records the number of times that L1-ICache accesses L2-Cache due to bus{i} accessing L1-ICache{i}.
0x1BC BUS0_ACS_HIT_CNT ro — L1-Cache bus0 Hit-Access Counter register
  [31:0] BUS0_HIT_CNT — The register records the number of hits when bus0 accesses L1-Cache.
0x1C0 BUS0_ACS_MISS_CNT ro — L1-Cache bus0 Miss-Access Counter register
  [31:0] BUS0_MISS_CNT — The register records the number of missing when bus0 accesses L1-Cache.
0x1C4 BUS0_ACS_CONFLICT_CNT ro — L1-Cache bus0 Conflict-Access Counter register
  [31:0] BUS0_CONFLICT_RD_CNT — The register records the number of access-conflicts when bus0 accesses L1-Cache.
0x1C8 DBUS0_ACS_NXTLVL_RD_CNT ro — L1-Cache bus0 Next-Level-Access Counter register
  [31:0] BUS0_NXTLVL_RD_CNT — The register records the number of times that L1-Cache accesses L2-Cache due to bus0 accessing L1-Cache.
0x1CC DBUS0_ACS_NXTLVL_WR_CNT ro — L1-DCache bus0 WB-Access Counter register
  [31:0] BUS0_NXTLVL_WR_CNT — The register records the number of write back when bus0 accesses L1-Cache.
0x1D0 BUS1_ACS_HIT_CNT ro — L1-Cache bus1 Hit-Access Counter register
  [31:0] BUS1_HIT_CNT — The register records the number of hits when bus1 accesses L1-Cache.
0x1D4 BUS1_ACS_MISS_CNT ro — L1-Cache bus1 Miss-Access Counter register
  [31:0] BUS1_MISS_CNT — The register records the number of missing when bus1 accesses L1-Cache.
0x1D8 BUS1_ACS_CONFLICT_CNT ro — L1-Cache bus1 Conflict-Access Counter register
  [31:0] BUS1_CONFLICT_CNT — The register records the number of access-conflicts when bus1 accesses L1-Cache.
{0x1C8+0x14*i} DBUS{i}_ACS_NXTLVL_RD_CNT ro (i=1..3) — L1-DCache bus{i} Next-Level-Access Counter register
  [31:0] DBUS{i}_NXTLVL_RD_CNT — The register records the number of times that L1-Cache accesses L2-Cache due to bus{i} accessing L1-Cache.
0x1E0 DBUS1_ACS_NXTLVL_WR_CNT ro — L1-DCache bus1 WB-Access Counter register
  [31:0] DBUS1_NXTLVL_WR_CNT — The register records the number of write back when bus1 accesses L1-Cache.
0x1E4 DBUS2_ACS_HIT_CNT ro — L1-DCache bus2 Hit-Access Counter register
  [31:0] DBUS2_HIT_CNT — The register records the number of hits when bus2 accesses L1-DCache.
0x1E8 DBUS2_ACS_MISS_CNT ro — L1-DCache bus2 Miss-Access Counter register
  [31:0] DBUS2_MISS_CNT — The register records the number of missing when bus2 accesses L1-DCache.
0x1EC DBUS2_ACS_CONFLICT_CNT ro — L1-DCache bus2 Conflict-Access Counter register
  [31:0] DBUS2_CONFLICT_CNT — The register records the number of access-conflicts when bus2 accesses L1-DCache.
0x1F4 DBUS2_ACS_NXTLVL_WR_CNT ro — L1-DCache bus2 WB-Access Counter register
  [31:0] DBUS2_NXTLVL_WR_CNT — The register records the number of write back when bus2 accesses L1-Cache.

## Notices in the file
Copyright 2025 Espressif Systems (Shanghai) PTE LTD
Licensed under the Apache License, Version 2.0 (the "License");
you may not use this file except in compliance with the License.
You may obtain a copy of the License at
http://www.apache.org/licenses/LICENSE-2.0
Unless required by applicable law or agreed to in writing, software
distributed under the License is distributed on an "AS IS" BASIS,
WITHOUT WARRANTIES OR CONDITIONS OF ANY KIND, either express or implied.
See the License for the specific language governing permissions and
limitations under the License.
